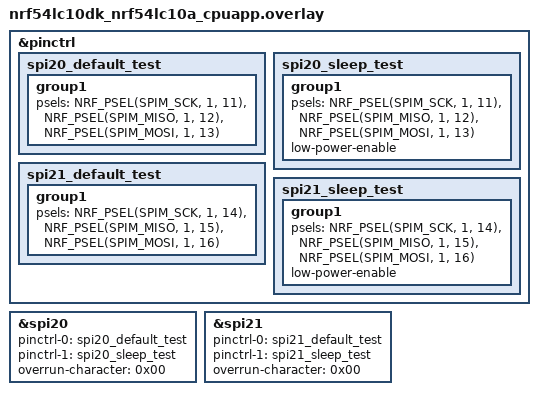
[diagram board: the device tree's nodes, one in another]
/*
 * Copyright (c) 2026 Nordic Semiconductor ASA
 *
 * SPDX-License-Identifier: LicenseRef-Nordic-5-Clause
 */

/*
 * Pinmux for nRF54LC10 DK (avoid DK buttons/LEDs and uart30 console on gpio0).
 * spi30 is not used (same address domain as uart30 used for console).
 */

&pinctrl {
	spi20_default_test: spi20_default_test {
		group1 {
			psels = <NRF_PSEL(SPIM_SCK, 1, 11)>,
				<NRF_PSEL(SPIM_MISO, 1, 12)>,
				<NRF_PSEL(SPIM_MOSI, 1, 13)>;
		};
	};

	spi20_sleep_test: spi20_sleep_test {
		group1 {
			psels = <NRF_PSEL(SPIM_SCK, 1, 11)>,
				<NRF_PSEL(SPIM_MISO, 1, 12)>,
				<NRF_PSEL(SPIM_MOSI, 1, 13)>;
			low-power-enable;
		};
	};

	spi21_default_test: spi21_default_test {
		group1 {
			psels = <NRF_PSEL(SPIM_SCK, 1, 14)>,
				<NRF_PSEL(SPIM_MISO, 1, 15)>,
				<NRF_PSEL(SPIM_MOSI, 1, 16)>;
		};
	};

	spi21_sleep_test: spi21_sleep_test {
		group1 {
			psels = <NRF_PSEL(SPIM_SCK, 1, 14)>,
				<NRF_PSEL(SPIM_MISO, 1, 15)>,
				<NRF_PSEL(SPIM_MOSI, 1, 16)>;
			low-power-enable;
		};
	};
};

&spi20 {
	status = "okay";
	pinctrl-0 = <&spi20_default_test>;
	pinctrl-1 = <&spi20_sleep_test>;
	pinctrl-names = "default", "sleep";
	overrun-character = <0x00>;
};

&spi21 {
	status = "okay";
	pinctrl-0 = <&spi21_default_test>;
	pinctrl-1 = <&spi21_sleep_test>;
	pinctrl-names = "default", "sleep";
	overrun-character = <0x00>;
};
